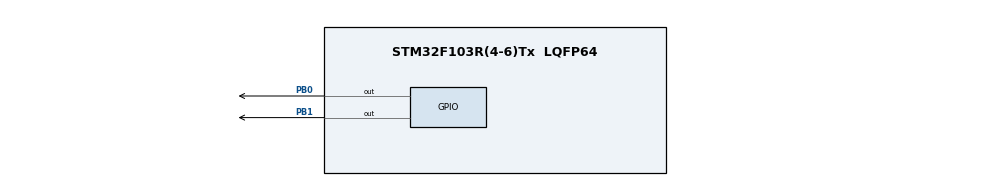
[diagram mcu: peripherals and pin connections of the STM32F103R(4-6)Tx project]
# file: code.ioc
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Mcu.Family=STM32F1
NVIC.TIM3_IRQn=true\:0\:0\:false\:false\:true\:true\:true
RCC.APB2Freq_Value=8000000
TIM3.Prescaler=999
Mcu.Name=STM32F103R(4-6)Tx
NVIC.TIM1_UP_IRQn=true\:0\:0\:false\:false\:true\:true\:true
VP_TIM1_VS_ClockSourceINT.Mode=Internal
VP_SYS_VS_ND.Mode=No_Debug
Mcu.Package=LQFP64
PB1.Signal=GPIO_Output
ProjectManager.StackSize=0x400
ProjectManager.HeapSize=0x200
TIM1.Prescaler=999
ProjectManager.TargetToolchain=Makefile
NVIC.PriorityGroup=NVIC_PRIORITYGROUP_4
TIM3.Period=3999
TIM1.Period=7999
RCC.APB1Freq_Value=8000000
PB0.Signal=GPIO_Output
VP_TIM3_VS_ClockSourceINT.Mode=Internal
board=custom

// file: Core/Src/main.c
/* USER CODE BEGIN Header */
/**
  ******************************************************************************
  * @file           : main.c
  * @brief          : Main program body
  ******************************************************************************
  * @attention
  *
  * <h2><center>&copy; Copyright (c) 2020 STMicroelectronics.
  * All rights reserved.</center></h2>
  *
  * This software component is licensed by ST under BSD 3-Clause license,
  * the "License"; You may not use this file except in compliance with the
  * License. You may obtain a copy of the License at:
  *                        opensource.org/licenses/BSD-3-Clause
  *
  ******************************************************************************
  */
/* USER CODE END Header */
#include "main.h"
#include "tim.h"
#include "gpio.h"

/* USER CODE BEGIN Includes */
#include "casovnik.h"
/* USER CODE END Includes */

void SystemClock_Config(void);

int main(void)
{

  /* MCU Configuration--------------------------------------------------------*/

  /* Reset of all peripherals, Initializes the Flash interface and the Systick. */
  HAL_Init();

  /* Configure the system clock */
  SystemClock_Config();

  /* Initialize all configured peripherals */
  MX_GPIO_Init();
  MX_TIM1_Init();
  MX_TIM3_Init();
  /* USER CODE BEGIN 2 */

  HAL_TIM_Base_Start_IT(&htim1);
  HAL_TIM_Base_Start_IT(&htim3);

  /* USER CODE END 2 */

  /* Infinite loop */
  while (1)
  {

  }
}

void SystemClock_Config(void)
{
  RCC_OscInitTypeDef RCC_OscInitStruct = {0};
  RCC_ClkInitTypeDef RCC_ClkInitStruct = {0};

  /** Initializes the RCC Oscillators according to the specified parameters
  * in the RCC_OscInitTypeDef structure.
  */
  RCC_OscInitStruct.OscillatorType = RCC_OSCILLATORTYPE_HSI;
  RCC_OscInitStruct.HSIState = RCC_HSI_ON;
  RCC_OscInitStruct.HSICalibrationValue = RCC_HSICALIBRATION_DEFAULT;
  RCC_OscInitStruct.PLL.PLLState = RCC_PLL_NONE;
  if (HAL_RCC_OscConfig(&RCC_OscInitStruct) != HAL_OK)
  {
    Error_Handler();
  }
  /** Initializes the CPU, AHB and APB buses clocks
  */
  RCC_ClkInitStruct.ClockType = RCC_CLOCKTYPE_HCLK|RCC_CLOCKTYPE_SYSCLK
                              |RCC_CLOCKTYPE_PCLK1|RCC_CLOCKTYPE_PCLK2;
  RCC_ClkInitStruct.SYSCLKSource = RCC_SYSCLKSOURCE_HSI;
  RCC_ClkInitStruct.AHBCLKDivider = RCC_SYSCLK_DIV1;
  RCC_ClkInitStruct.APB1CLKDivider = RCC_HCLK_DIV1;
  RCC_ClkInitStruct.APB2CLKDivider = RCC_HCLK_DIV1;

  if (HAL_RCC_ClockConfig(&RCC_ClkInitStruct, FLASH_LATENCY_0) != HAL_OK)
  {
    Error_Handler();
  }
}

void Error_Handler(void)
{
}

/************************ (C) COPYRIGHT STMicroelectronics *****END OF FILE****/
